# ioam3358 register map
Registers are 32-bit, access not given, no defined reset value unless marked. A register's access mark holds for its fields unless they carry their own. Addresses are absolute; registers are grouped by the start of their names; [hi:lo] are bit positions; {n}, {i} and the like mark numbered series.

## GPMC
0x50000000 GPMC_REVISION
  [7:0] REV
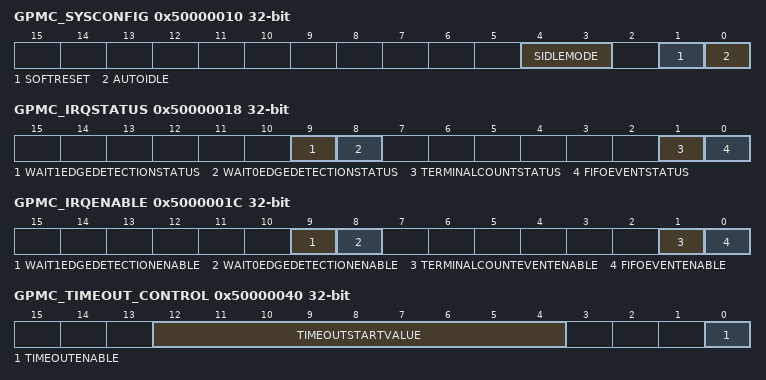
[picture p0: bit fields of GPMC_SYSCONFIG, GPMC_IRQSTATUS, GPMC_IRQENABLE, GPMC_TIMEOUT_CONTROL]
0x50000010 GPMC_SYSCONFIG
  [4:3] SIDLEMODE, [1] SOFTRESET, [0] AUTOIDLE
0x50000014 GPMC_SYSSTATUS
  [0] RESETDONE
0x50000018 GPMC_IRQSTATUS
  [9] WAIT1EDGEDETECTIONSTATUS, [8] WAIT0EDGEDETECTIONSTATUS, [1] TERMINALCOUNTSTATUS, [0] FIFOEVENTSTATUS
0x5000001C GPMC_IRQENABLE
  [9] WAIT1EDGEDETECTIONENABLE, [8] WAIT0EDGEDETECTIONENABLE, [1] TERMINALCOUNTEVENTENABLE, [0] FIFOEVENTENABLE
0x50000040 GPMC_TIMEOUT_CONTROL
  [12:4] TIMEOUTSTARTVALUE, [0] TIMEOUTENABLE
0x50000044 GPMC_ERR_ADDRESS
  [30:0] ILLEGALADD
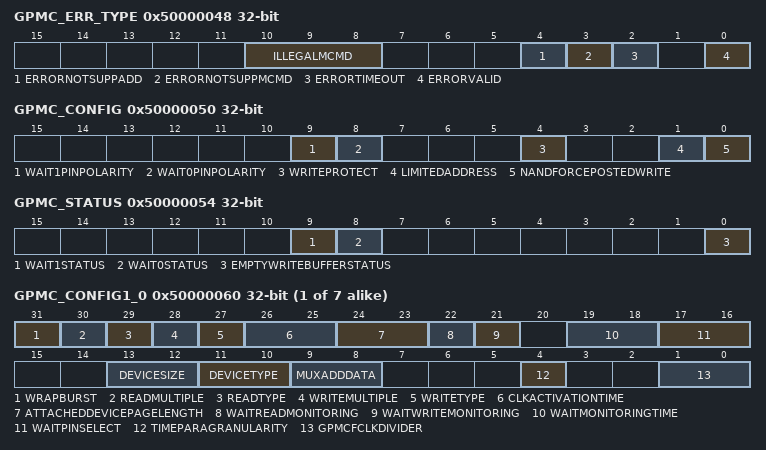
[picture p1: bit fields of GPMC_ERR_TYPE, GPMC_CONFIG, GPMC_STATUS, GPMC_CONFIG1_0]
0x50000048 GPMC_ERR_TYPE
  [10:8] ILLEGALMCMD, [4] ERRORNOTSUPPADD, [3] ERRORNOTSUPPMCMD, [2] ERRORTIMEOUT, [0] ERRORVALID
0x50000050 GPMC_CONFIG
  [9] WAIT1PINPOLARITY, [8] WAIT0PINPOLARITY, [4] WRITEPROTECT, [1] LIMITEDADDRESS, [0] NANDFORCEPOSTEDWRITE
0x50000054 GPMC_STATUS
  [9] WAIT1STATUS, [8] WAIT0STATUS, [0] EMPTYWRITEBUFFERSTATUS
{0x50000060+0x30*i} GPMC_CONFIG1_{i} (i=0..6)
  [31] WRAPBURST, [30] READMULTIPLE, [29] READTYPE, [28] WRITEMULTIPLE, [27] WRITETYPE, [26:25] CLKACTIVATIONTIME, [24:23] ATTACHEDDEVICEPAGELENGTH, [22] WAITREADMONITORING, [21] WAITWRITEMONITORING, [19:18] WAITMONITORINGTIME, [17:16] WAITPINSELECT, [13:12] DEVICESIZE, [11:10] DEVICETYPE, [9:8] MUXADDDATA, [4] TIMEPARAGRANULARITY, [1:0] GPMCFCLKDIVIDER
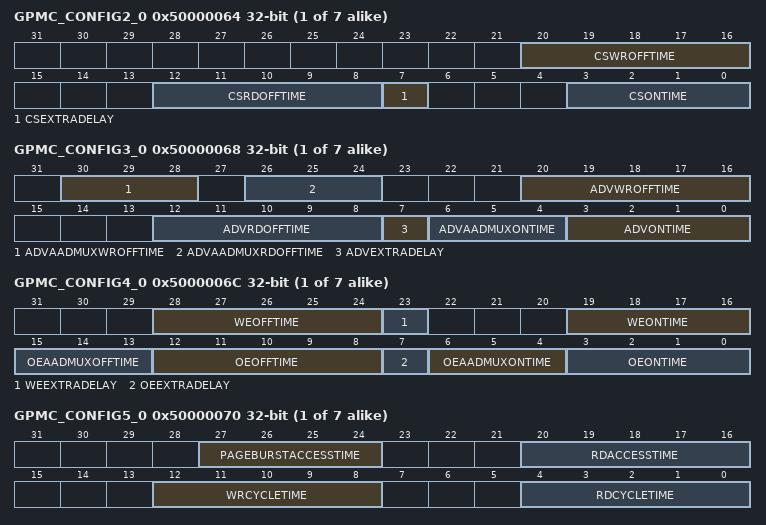
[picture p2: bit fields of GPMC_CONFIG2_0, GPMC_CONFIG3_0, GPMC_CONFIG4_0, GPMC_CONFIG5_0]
{0x50000064+0x30*i} GPMC_CONFIG2_{i} (i=0..6)
  [20:16] CSWROFFTIME, [12:8] CSRDOFFTIME, [7] CSEXTRADELAY, [3:0] CSONTIME
{0x50000068+0x30*i} GPMC_CONFIG3_{i} (i=0..6)
  [30:28] ADVAADMUXWROFFTIME, [26:24] ADVAADMUXRDOFFTIME, [20:16] ADVWROFFTIME, [12:8] ADVRDOFFTIME, [7] ADVEXTRADELAY, [6:4] ADVAADMUXONTIME, [3:0] ADVONTIME
{0x5000006C+0x30*i} GPMC_CONFIG4_{i} (i=0..6)
  [28:24] WEOFFTIME, [23] WEEXTRADELAY, [19:16] WEONTIME, [15:13] OEAADMUXOFFTIME, [12:8] OEOFFTIME, [7] OEEXTRADELAY, [6:4] OEAADMUXONTIME, [3:0] OEONTIME
{0x50000070+0x30*i} GPMC_CONFIG5_{i} (i=0..6)
  [27:24] PAGEBURSTACCESSTIME, [20:16] RDACCESSTIME, [12:8] WRCYCLETIME, [4:0] RDCYCLETIME
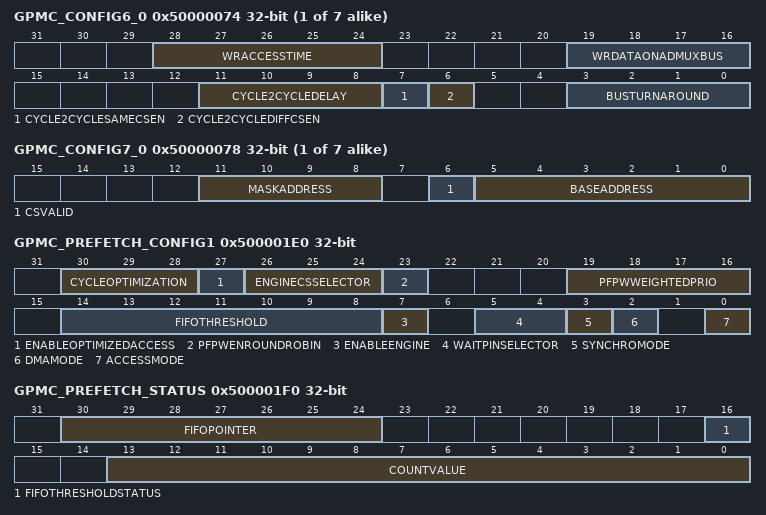
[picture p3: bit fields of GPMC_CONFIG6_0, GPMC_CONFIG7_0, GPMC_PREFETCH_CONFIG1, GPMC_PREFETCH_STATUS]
{0x50000074+0x30*i} GPMC_CONFIG6_{i} (i=0..6)
  [28:24] WRACCESSTIME, [19:16] WRDATAONADMUXBUS, [11:8] CYCLE2CYCLEDELAY, [7] CYCLE2CYCLESAMECSEN, [6] CYCLE2CYCLEDIFFCSEN, [3:0] BUSTURNAROUND
{0x50000078+0x30*i} GPMC_CONFIG7_{i} (i=0..6)
  [11:8] MASKADDRESS, [6] CSVALID, [5:0] BASEADDRESS
{0x5000007C+0x30*i} GPMC_NAND_COMMAND_{i} (i=0..6)
{0x50000080+0x30*i} GPMC_NAND_ADDRESS_{i} (i=0..6)
{0x50000084+0x30*i} GPMC_NAND_DATA_{i} (i=0..6)
0x500001E0 GPMC_PREFETCH_CONFIG1
  [30:28] CYCLEOPTIMIZATION, [27] ENABLEOPTIMIZEDACCESS, [26:24] ENGINECSSELECTOR, [23] PFPWENROUNDROBIN, [19:16] PFPWWEIGHTEDPRIO, [14:8] FIFOTHRESHOLD, [7] ENABLEENGINE, [5:4] WAITPINSELECTOR, [3] SYNCHROMODE, [2] DMAMODE, [0] ACCESSMODE
0x500001E4 GPMC_PREFETCH_CONFIG2
  [13:0] TRANSFERCOUNT
0x500001EC GPMC_PREFETCH_CONTROL
  [0] STARTENGINE
0x500001F0 GPMC_PREFETCH_STATUS
  [30:24] FIFOPOINTER, [16] FIFOTHRESHOLDSTATUS, [13:0] COUNTVALUE
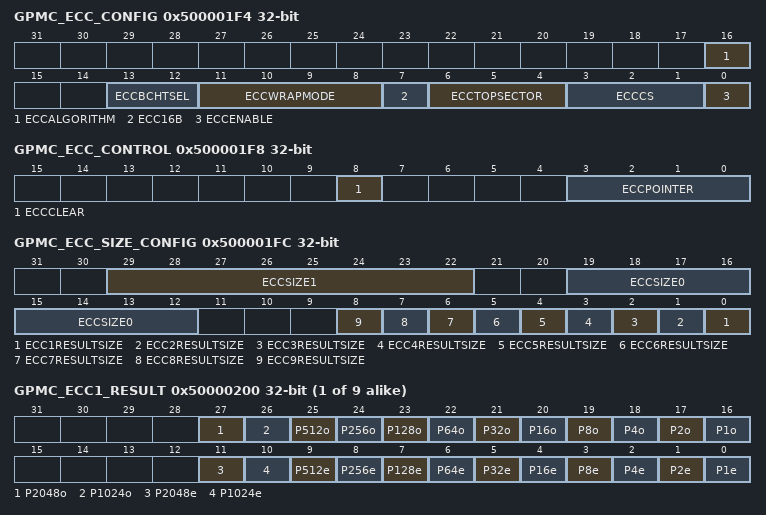
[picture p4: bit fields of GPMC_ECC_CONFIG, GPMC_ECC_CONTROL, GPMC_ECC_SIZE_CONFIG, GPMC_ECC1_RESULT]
0x500001F4 GPMC_ECC_CONFIG
  [16] ECCALGORITHM, [13:12] ECCBCHTSEL, [11:8] ECCWRAPMODE, [7] ECC16B, [6:4] ECCTOPSECTOR, [3:1] ECCCS, [0] ECCENABLE
0x500001F8 GPMC_ECC_CONTROL
  [8] ECCCLEAR, [3:0] ECCPOINTER
0x500001FC GPMC_ECC_SIZE_CONFIG
  [29:22] ECCSIZE1, [19:12] ECCSIZE0, [n-1] ECC{n}RESULTSIZE (n=1..9)
{0x500001FC+4i} GPMC_ECC{i}_RESULT (i=1..9)
  [27] P2048o, [26] P1024o, [25] P512o, [24] P256o, [23] P128o, [22] P64o, [21] P32o, [20] P16o, [19] P8o, [18] P4o, [17] P2o, [16] P1o, [11] P2048e, [10] P1024e, [9] P512e, [8] P256e, [7] P128e, [6] P64e, [5] P32e, [4] P16e, [3] P8e, [2] P4e, [1] P2e, [0] P1e
{0x50000240+0x10*i} GPMC_BCH_RESULT0_{i} (i=0..6)
{0x50000244+0x10*i} GPMC_BCH_RESULT1_{i} (i=0..6)
{0x50000248+0x10*i} GPMC_BCH_RESULT2_{i} (i=0..6)
{0x5000024C+0x10*i} GPMC_BCH_RESULT3_{i} (i=0..6)
0x500002D0 GPMC_BCH_SWDATA
  [15:0] BCH_DATA
{0x50000300+0x10*i} GPMC_BCH_RESULT4_{i} (i=0..6)
{0x50000304+0x10*i} GPMC_BCH_RESULT5_{i} (i=0..6)
{0x50000308+0x10*i} GPMC_BCH_RESULT6_{i} (i=0..6)
